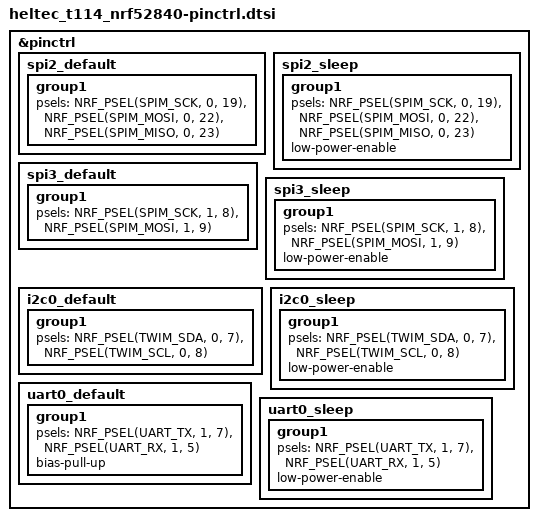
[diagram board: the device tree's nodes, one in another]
/*
 * Heltec T114 pin control definitions
 * Copyright (c) 2026 ZephCore
 *
 * SPDX-License-Identifier: Apache-2.0
 *
 * Pin mappings from MeshCore variants/heltec_t114 (variant.cpp, platformio.ini):
 * - SPI2 (SX1262 LoRa): SCK=P0.19, MOSI=P0.22, MISO=P0.23
 * - SPI3 (ST7789 display): SCK=P1.08 (PIN_TFT_SCL=40), MOSI=P1.09 (PIN_TFT_SDA=41)
 * - I2C0 (Wire1, sensors): SDA=P0.07, SCL=P0.08
 * - UART0 (GPS): TX=P1.07, RX=P1.05
 */

&pinctrl {
	spi2_default: spi2_default {
		group1 {
			psels = <NRF_PSEL(SPIM_SCK, 0, 19)>,
				<NRF_PSEL(SPIM_MOSI, 0, 22)>,
				<NRF_PSEL(SPIM_MISO, 0, 23)>;
		};
	};

	spi2_sleep: spi2_sleep {
		group1 {
			psels = <NRF_PSEL(SPIM_SCK, 0, 19)>,
				<NRF_PSEL(SPIM_MOSI, 0, 22)>,
				<NRF_PSEL(SPIM_MISO, 0, 23)>;
			low-power-enable;
		};
	};

	spi3_default: spi3_default {
		group1 {
			psels = <NRF_PSEL(SPIM_SCK,  1, 8)>,
				<NRF_PSEL(SPIM_MOSI, 1, 9)>;
		};
	};

	spi3_sleep: spi3_sleep {
		group1 {
			psels = <NRF_PSEL(SPIM_SCK,  1, 8)>,
				<NRF_PSEL(SPIM_MOSI, 1, 9)>;
			low-power-enable;
		};
	};

	i2c0_default: i2c0_default {
		group1 {
			psels = <NRF_PSEL(TWIM_SDA, 0, 7)>,
				<NRF_PSEL(TWIM_SCL, 0, 8)>;
		};
	};

	i2c0_sleep: i2c0_sleep {
		group1 {
			psels = <NRF_PSEL(TWIM_SDA, 0, 7)>,
				<NRF_PSEL(TWIM_SCL, 0, 8)>;
			low-power-enable;
		};
	};

	uart0_default: uart0_default {
		group1 {
			psels = <NRF_PSEL(UART_TX, 1, 7)>,
				<NRF_PSEL(UART_RX, 1, 5)>;
			bias-pull-up;
		};
	};

	uart0_sleep: uart0_sleep {
		group1 {
			psels = <NRF_PSEL(UART_TX, 1, 7)>,
				<NRF_PSEL(UART_RX, 1, 5)>;
			low-power-enable;
		};
	};
};
